# MSS_GPADC_PKT_RAM register map
Vendor: Texas Instruments
Peripheral module from a debugger description file (folder awr2544).
Registers are 32-bit, read-write, no defined reset value unless marked. A register's access mark holds for its fields unless they carry their own. Offsets are as the file gives them; lines under a group give offsets from that group; [hi:lo] are bit positions; {n}, {i} and the like mark numbered series; 'fields as' and 'values as' point back to an identical list; <NAME> marks a mode.

## MSS_GPADC_PKT_RAM
0x00 INST0_0
  [31:0] CONFIG_VALUE — configuration value to be passed to analog
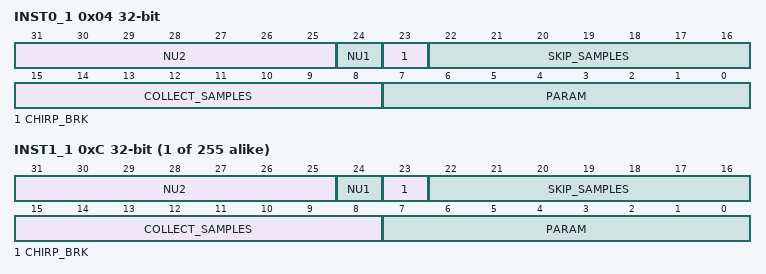
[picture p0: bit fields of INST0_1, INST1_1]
0x04 INST0_1 access per field
  [31:25] NU2 ro
  [24] NU1 ro — 1:Continue tests from the next instruction for the next chirp with the same profile
  [23] CHIRP_BRK rw
  [22:16] SKIP_SAMPLES rw — Number of GPADC clock cycles to skip before collecting valid samples
  [15:8] COLLECT_SAMPLES rw — Number of GPADC samples to collect
  [7:0] PARAM rw — Parameter(input to one hot encoding) to be passed to analog
{0x0+8i} INST{i}_0 (i=1..255)
  [31:0] CONFIG_VALUE
{0x4+8i} INST{i}_1 access per field (i=1..255)
  [31:25] NU2 ro, [24] NU1 ro, [23] CHIRP_BRK rw, [22:16] SKIP_SAMPLES rw, [15:8] COLLECT_SAMPLES rw, [7:0] PARAM rw
